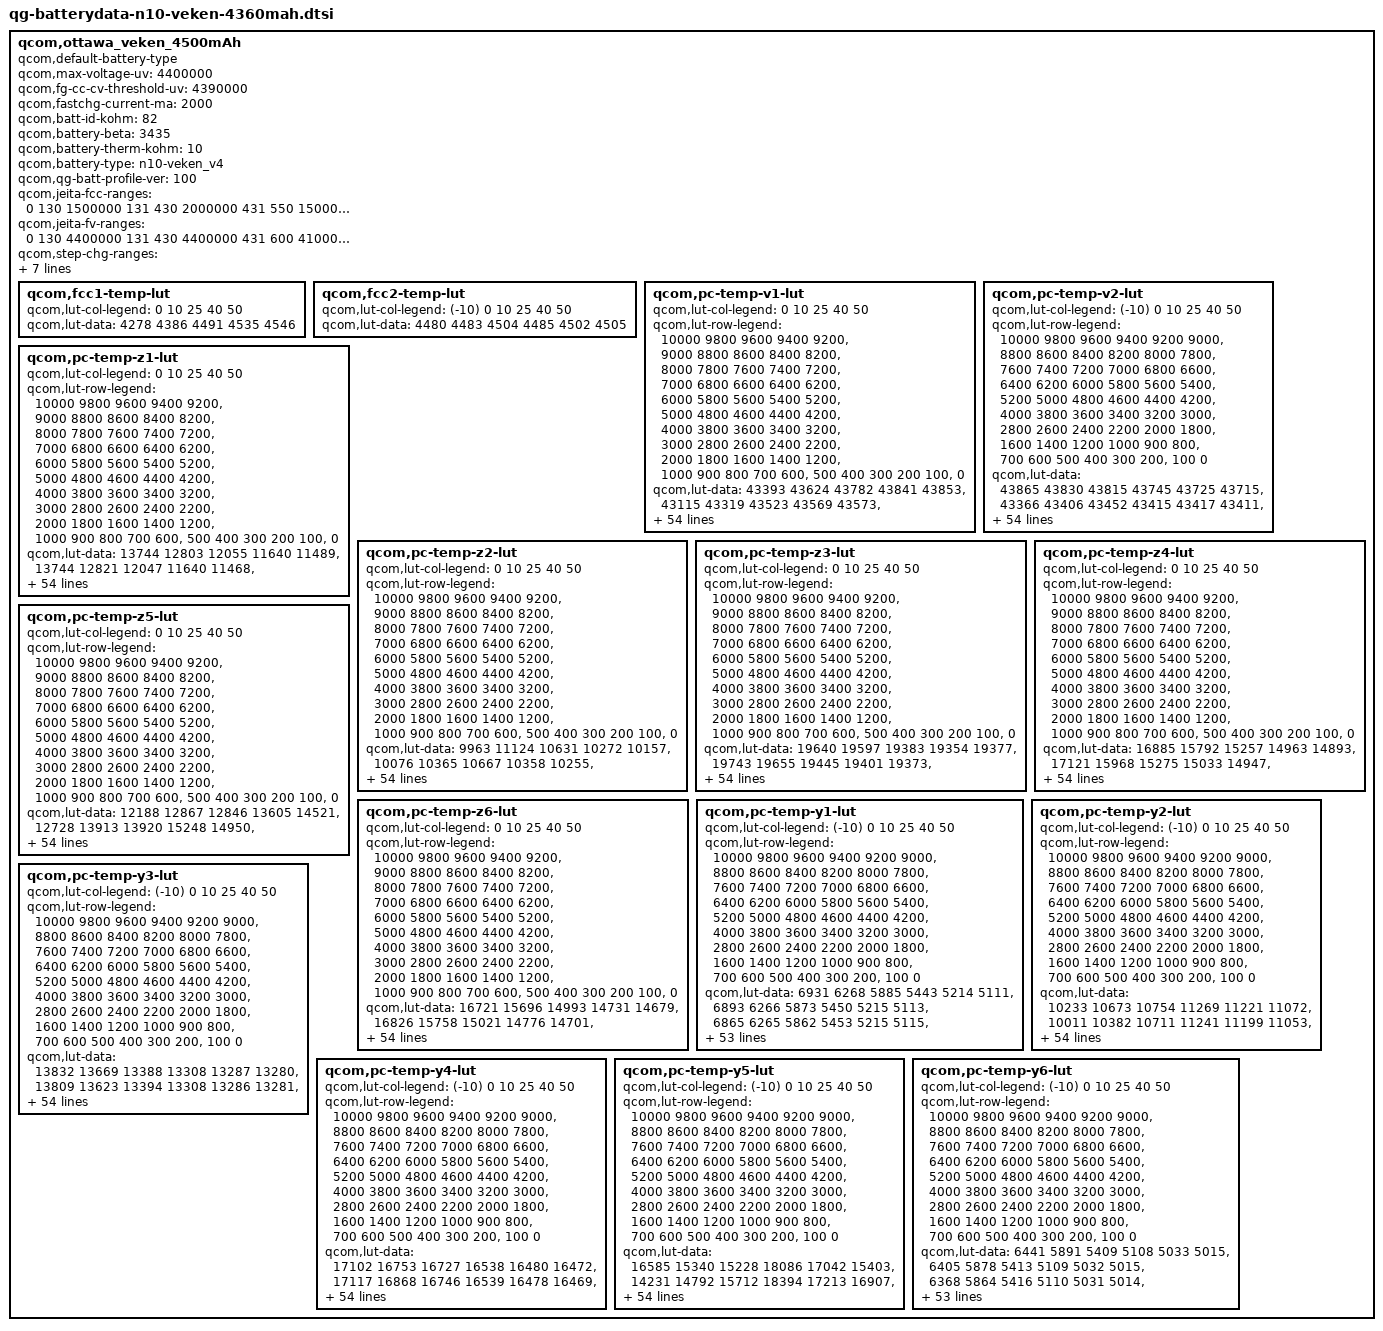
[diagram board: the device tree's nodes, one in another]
/*
 * Copyright (c) 2018, The Linux Foundation. All rights reserved.
 *
 * This program is free software; you can redistribute it and/or modify
 * it under the terms of the GNU General Public License version 2 and
 * only version 2 as published by the Free Software Foundation.
 *
 * This program is distributed in the hope that it will be useful,
 * but WITHOUT ANY WARRANTY; without even the implied warranty of
 * MERCHANTABILITY or FITNESS FOR A PARTICULAR PURPOSE.  See the
 * GNU General Public License for more details.
 */

qcom,ottawa_veken_4500mAh {
	/* 4251176_TCL_T1Pro_Veken_4500mAH_PM6150_averaged_MasterSlave_Nov29th2019 */
	qcom,default-battery-type;
	qcom,max-voltage-uv = <4400000>;
	qcom,fg-cc-cv-threshold-uv = <4390000>;
	qcom,fastchg-current-ma = <2000>;
	qcom,batt-id-kohm = <82>;
	qcom,battery-beta = <3435>;
	qcom,battery-therm-kohm = <10>;
	qcom,battery-type = "n10-veken_v4";
	qcom,qg-batt-profile-ver = <100>;

	qcom,jeita-fcc-ranges = <0  130   1500000
				131  430  2000000
				431 550   1500000
				551 600   0>;
	qcom,jeita-fv-ranges = <0   130   4400000
				131  430  4400000
				431  600  4100000>;
	qcom,step-chg-ranges = <2800000  4250000  2000000
				4250001  4400000  1800000>;
	qcom,ocv-based-step-chg;

	/* COOL = 10 DegC, WARM = 45 DegC */
	qcom,jeita-soft-thresholds = <0x2aee 0xfb3>;
	/* COLD = 0 DegC, HOT = 55 DegC */
	qcom,jeita-hard-thresholds = <0x3733 0xbc2>;
	/* COOL hys = 13 DegC, WARM hys = 42 DegC */
	qcom,jeita-soft-hys-thresholds = <0x279a 0x1124>;

	qcom,jeita-soft-fcc-ua = <2000000 2000000>;
	qcom,jeita-soft-fv-uv = <4100000 4100000>;

	qcom,fcc1-temp-lut {
		qcom,lut-col-legend = <0 10 25 40 50>;
		qcom,lut-data = <4278 4386 4491 4535 4546>;
	};

	qcom,fcc2-temp-lut {
		qcom,lut-col-legend = <(-10) 0 10 25 40 50>;
		qcom,lut-data = <4480 4483 4504 4485 4502 4505>;
	};

	qcom,pc-temp-v1-lut {
		qcom,lut-col-legend = <0 10 25 40 50>;
		qcom,lut-row-legend = <10000 9800 9600 9400 9200>,
			<9000 8800 8600 8400 8200>,
			<8000 7800 7600 7400 7200>,
			<7000 6800 6600 6400 6200>,
			<6000 5800 5600 5400 5200>,
			<5000 4800 4600 4400 4200>,
			<4000 3800 3600 3400 3200>,
			<3000 2800 2600 2400 2200>,
			<2000 1800 1600 1400 1200>,
			<1000 900 800 700 600>,
			<500 400 300 200 100>,
			<0>;
		qcom,lut-data = <43393 43624 43782 43841 43853>,
			<43115 43319 43523 43569 43573>,
			<42856 43056 43264 43311 43316>,
			<42614 42817 43011 43062 43070>,
			<42386 42585 42761 42820 42829>,
			<42167 42356 42515 42583 42593>,
			<41955 42131 42280 42349 42360>,
			<41749 41914 42052 42119 42128>,
			<41553 41702 41827 41891 41899>,
			<41373 41500 41603 41666 41673>,
			<41195 41318 41389 41443 41450>,
			<40987 41139 41199 41223 41231>,
			<40741 40927 41016 41004 41014>,
			<40489 40666 40798 40795 40805>,
			<40246 40409 40538 40592 40605>,
			<40011 40184 40302 40398 40412>,
			<39831 39979 40118 40213 40226>,
			<39708 39823 39958 40037 40048>,
			<39605 39713 39812 39869 39877>,
			<39498 39610 39681 39719 39723>,
			<39390 39489 39540 39563 39566>,
			<39285 39359 39367 39370 39377>,
			<39179 39217 39173 39148 39156>,
			<39074 39045 38970 38950 38958>,
			<38973 38866 38749 38777 38788>,
			<38877 38706 38591 38633 38644>,
			<38784 38553 38508 38529 38536>,
			<38693 38444 38446 38446 38449>,
			<38604 38377 38385 38367 38367>,
			<38525 38327 38325 38290 38284>,
			<38458 38291 38270 38220 38208>,
			<38397 38266 38218 38156 38139>,
			<38345 38244 38170 38099 38076>,
			<38301 38221 38129 38047 38018>,
			<38262 38199 38094 38003 37968>,
			<38228 38173 38059 37960 37919>,
			<38196 38146 38027 37916 37868>,
			<38159 38110 37991 37873 37815>,
			<38109 38058 37939 37813 37748>,
			<38046 37982 37856 37731 37659>,
			<37960 37889 37758 37633 37558>,
			<37836 37768 37649 37528 37450>,
			<37707 37627 37519 37404 37327>,
			<37572 37459 37353 37243 37169>,
			<37410 37302 37200 37094 37028>,
			<37287 37195 37094 37002 36941>,
			<37245 37163 37068 36971 36911>,
			<37209 37140 37045 36950 36893>,
			<37177 37123 37031 36935 36873>,
			<37136 37092 36999 36900 36833>,
			<37004 36954 36834 36711 36613>,
			<36611 36535 36417 36291 36190>,
			<36050 35982 35856 35726 35629>,
			<35301 35225 35096 34958 34860>,
			<34109 34044 33919 33769 33670>,
			<30000 30000 30000 30000 30000>;
	};

	qcom,pc-temp-v2-lut {
		qcom,lut-col-legend = <(-10) 0 10 25 40 50>;
		qcom,lut-row-legend = <10000 9800 9600 9400 9200 9000>,
			<8800 8600 8400 8200 8000 7800>,
			<7600 7400 7200 7000 6800 6600>,
			<6400 6200 6000 5800 5600 5400>,
			<5200 5000 4800 4600 4400 4200>,
			<4000 3800 3600 3400 3200 3000>,
			<2800 2600 2400 2200 2000 1800>,
			<1600 1400 1200 1000 900 800>,
			<700 600 500 400 300 200>,
			<100 0>;
		qcom,lut-data = <43865 43830 43815 43745 43725 43715>,
			<43366 43406 43452 43415 43417 43411>,
			<42943 43029 43124 43112 43130 43127>,
			<42618 42705 42837 42840 42867 42866>,
			<42366 42422 42588 42599 42626 42627>,
			<42130 42178 42350 42366 42392 42393>,
			<41874 41982 42111 42132 42157 42160>,
			<41630 41806 41877 41902 41926 41928>,
			<41447 41586 41646 41676 41699 41700>,
			<41308 41299 41412 41453 41474 41475>,
			<41178 41101 41201 41237 41254 41254>,
			<41052 41043 41039 41040 41040 41037>,
			<40911 41005 40886 40849 40831 40825>,
			<40649 40846 40677 40631 40624 40620>,
			<40090 40280 40391 40375 40416 40420>,
			<39611 39788 40125 40143 40219 40229>,
			<39405 39621 39924 39970 40042 40047>,
			<39257 39507 39745 39822 39876 39873>,
			<39089 39358 39561 39678 39714 39708>,
			<38903 39169 39380 39545 39563 39557>,
			<38730 38979 39195 39393 39396 39391>,
			<38579 38798 38995 39176 39180 39182>,
			<38447 38626 38796 38926 38950 38959>,
			<38349 38468 38626 38730 38761 38772>,
			<38275 38314 38476 38572 38600 38605>,
			<38211 38198 38340 38439 38463 38465>,
			<38151 38133 38202 38329 38352 38352>,
			<38094 38086 38080 38233 38256 38255>,
			<38039 38042 38011 38144 38169 38167>,
			<37988 38000 37969 38061 38090 38087>,
			<37937 37960 37932 37987 38020 38016>,
			<37884 37921 37895 37918 37956 37952>,
			<37830 37883 37860 37858 37897 37893>,
			<37772 37843 37826 37808 37834 37828>,
			<37713 37799 37795 37770 37770 37760>,
			<37652 37752 37759 37731 37701 37683>,
			<37590 37700 37715 37684 37624 37586>,
			<37529 37643 37663 37631 37542 37483>,
			<37465 37579 37600 37568 37464 37396>,
			<37401 37507 37525 37495 37390 37321>,
			<37337 37425 37440 37411 37309 37243>,
			<37277 37320 37342 37312 37218 37157>,
			<37216 37202 37227 37194 37113 37057>,
			<37149 37098 37086 37056 36981 36919>,
			<37070 37011 36954 36924 36859 36807>,
			<36967 36941 36866 36853 36802 36754>,
			<36910 36903 36839 36838 36793 36745>,
			<36839 36867 36816 36823 36778 36733>,
			<36749 36817 36781 36799 36756 36709>,
			<36615 36726 36712 36749 36697 36641>,
			<36387 36528 36527 36566 36455 36372>,
			<36028 36131 36110 36123 35975 35888>,
			<35480 35537 35492 35520 35347 35250>,
			<34654 34677 34618 34705 34497 34385>,
			<33273 33360 33302 33477 33279 33164>,
			<29440 28853 28714 28637 28563 28582>;
	};

	qcom,pc-temp-z1-lut {
		qcom,lut-col-legend = <0 10 25 40 50>;
		qcom,lut-row-legend = <10000 9800 9600 9400 9200>,
			<9000 8800 8600 8400 8200>,
			<8000 7800 7600 7400 7200>,
			<7000 6800 6600 6400 6200>,
			<6000 5800 5600 5400 5200>,
			<5000 4800 4600 4400 4200>,
			<4000 3800 3600 3400 3200>,
			<3000 2800 2600 2400 2200>,
			<2000 1800 1600 1400 1200>,
			<1000 900 800 700 600>,
			<500 400 300 200 100>,
			<0>;
		qcom,lut-data = <13744 12803 12055 11640 11489>,
			<13744 12821 12047 11640 11468>,
			<13761 12814 12043 11637 11471>,
			<13769 12790 12038 11633 11472>,
			<13743 12773 12030 11626 11468>,
			<13704 12768 12021 11618 11462>,
			<13692 12765 12012 11611 11458>,
			<13699 12760 12003 11603 11455>,
			<13708 12749 11998 11599 11453>,
			<13711 12737 11995 11597 11452>,
			<13698 12730 11994 11596 11451>,
			<13661 12723 11996 11597 11451>,
			<13593 12707 12000 11600 11451>,
			<13544 12665 11996 11601 11451>,
			<13526 12633 11975 11596 11451>,
			<13509 12629 11962 11590 11451>,
			<13492 12628 11964 11590 11451>,
			<13466 12630 11967 11592 11452>,
			<13443 12642 11971 11594 11453>,
			<13433 12658 11982 11597 11454>,
			<13427 12674 11991 11599 11455>,
			<13422 12692 11996 11601 11455>,
			<13415 12703 12000 11602 11456>,
			<13410 12708 12003 11603 11457>,
			<13409 12713 12005 11604 11458>,
			<13413 12720 12007 11606 11461>,
			<13420 12737 12011 11609 11463>,
			<13433 12745 12018 11614 11467>,
			<13453 12739 12022 11618 11470>,
			<13463 12729 12026 11623 11474>,
			<13462 12729 12030 11627 11478>,
			<13459 12740 12033 11632 11482>,
			<13466 12752 12036 11636 11485>,
			<13497 12759 12044 11641 11488>,
			<13523 12766 12061 11645 11493>,
			<13522 12775 12071 11650 11497>,
			<13515 12785 12071 11653 11500>,
			<13519 12798 12070 11657 11503>,
			<13538 12818 12071 11661 11505>,
			<13565 12846 12080 11668 11509>,
			<13597 12859 12090 11675 11512>,
			<13638 12857 12099 11680 11516>,
			<13641 12860 12108 11684 11520>,
			<13602 12883 12120 11687 11523>,
			<13660 12912 12123 11694 11527>,
			<13638 12883 12138 11698 11529>,
			<13667 12891 12129 11698 11529>,
			<13644 12899 12125 11699 11531>,
			<13611 12903 12136 11702 11532>,
			<13615 12895 12140 11710 11538>,
			<13631 12919 12162 11720 11545>,
			<13658 12930 12160 11731 11555>,
			<13663 12939 12176 11741 11567>,
			<13671 12970 12219 11763 11583>,
			<13671 12970 12219 11763 11583>,
			<13671 12970 12219 11763 11583>;
	};

	qcom,pc-temp-z2-lut {
		qcom,lut-col-legend = <0 10 25 40 50>;
		qcom,lut-row-legend = <10000 9800 9600 9400 9200>,
			<9000 8800 8600 8400 8200>,
			<8000 7800 7600 7400 7200>,
			<7000 6800 6600 6400 6200>,
			<6000 5800 5600 5400 5200>,
			<5000 4800 4600 4400 4200>,
			<4000 3800 3600 3400 3200>,
			<3000 2800 2600 2400 2200>,
			<2000 1800 1600 1400 1200>,
			<1000 900 800 700 600>,
			<500 400 300 200 100>,
			<0>;
		qcom,lut-data = <9963 11124 10631 10272 10157>,
			<10076 10365 10667 10358 10255>,
			<10162 10264 11033 10412 10354>,
			<10193 10242 11098 10443 10408>,
			<10200 10229 10708 10419 10392>,
			<10206 10214 10376 10389 10357>,
			<10209 10201 10438 10484 10330>,
			<10206 10191 10596 10747 10307>,
			<10201 10182 10615 10838 10296>,
			<10197 10175 10426 11039 10292>,
			<10193 10173 10275 11347 10288>,
			<10185 10171 10376 11221 10287>,
			<10158 10163 10582 10638 10292>,
			<10125 10147 10632 10391 10291>,
			<10099 10138 10510 10992 10250>,
			<10077 10142 10402 11670 10197>,
			<10068 10157 10394 11470 10196>,
			<10066 10176 10390 10685 10225>,
			<10064 10209 10397 10352 10254>,
			<10065 10247 10428 10363 10271>,
			<10071 10282 10467 10384 10293>,
			<10079 10318 10515 10450 10376>,
			<10086 10349 10559 10578 10561>,
			<10094 10380 10565 10620 10638>,
			<10102 10402 10548 10551 10540>,
			<10112 10402 10534 10481 10418>,
			<10125 10398 10522 10465 10389>,
			<10138 10396 10508 10455 10376>,
			<10153 10409 10511 10456 10379>,
			<10170 10432 10527 10485 10419>,
			<10190 10444 10540 10511 10456>,
			<10212 10453 10544 10503 10449>,
			<10234 10460 10548 10484 10416>,
			<10255 10468 10557 10478 10382>,
			<10276 10477 10572 10481 10336>,
			<10296 10489 10586 10486 10304>,
			<10315 10503 10594 10503 10323>,
			<10340 10520 10602 10535 10380>,
			<10375 10541 10616 10566 10438>,
			<10416 10566 10640 10608 10516>,
			<10456 10588 10659 10635 10571>,
			<10498 10603 10672 10639 10580>,
			<10397 10622 10679 10641 10584>,
			<9842 10648 10679 10638 10576>,
			<10019 10872 10733 10646 10533>,
			<10644 10958 10788 10562 10485>,
			<10246 11003 10795 10571 10468>,
			<10415 11128 10778 10567 10484>,
			<11495 11535 10858 10596 10493>,
			<12809 11438 10902 10673 10573>,
			<12857 11091 10914 10644 10472>,
			<10270 11041 10831 10523 10314>,
			<10331 11022 10759 10460 10267>,
			<10140 10655 10778 10420 10209>,
			<10140 10655 10778 10420 10209>,
			<10140 10655 10778 10420 10209>;
	};

	qcom,pc-temp-z3-lut {
		qcom,lut-col-legend = <0 10 25 40 50>;
		qcom,lut-row-legend = <10000 9800 9600 9400 9200>,
			<9000 8800 8600 8400 8200>,
			<8000 7800 7600 7400 7200>,
			<7000 6800 6600 6400 6200>,
			<6000 5800 5600 5400 5200>,
			<5000 4800 4600 4400 4200>,
			<4000 3800 3600 3400 3200>,
			<3000 2800 2600 2400 2200>,
			<2000 1800 1600 1400 1200>,
			<1000 900 800 700 600>,
			<500 400 300 200 100>,
			<0>;
		qcom,lut-data = <19640 19597 19383 19354 19377>,
			<19743 19655 19445 19401 19373>,
			<19781 19682 19476 19427 19397>,
			<19786 19702 19493 19439 19414>,
			<19748 19708 19509 19443 19424>,
			<19703 19701 19520 19447 19430>,
			<19688 19690 19527 19453 19431>,
			<19681 19682 19532 19465 19430>,
			<19678 19674 19530 19468 19427>,
			<19681 19667 19515 19468 19421>,
			<19688 19658 19502 19467 19412>,
			<19701 19649 19499 19455 19407>,
			<19729 19644 19499 19429 19404>,
			<19755 19641 19497 19418 19400>,
			<19762 19637 19490 19429 19393>,
			<19765 19628 19480 19441 19385>,
			<19764 19613 19471 19433 19380>,
			<19748 19595 19461 19408 19377>,
			<19722 19568 19455 19392 19374>,
			<19703 19547 19450 19385 19369>,
			<19686 19544 19448 19381 19365>,
			<19678 19545 19452 19386 19368>,
			<19681 19548 19459 19400 19378>,
			<19693 19561 19462 19404 19383>,
			<19703 19575 19460 19396 19375>,
			<19711 19578 19458 19386 19364>,
			<19718 19578 19454 19380 19360>,
			<19722 19578 19449 19377 19358>,
			<19724 19576 19449 19376 19358>,
			<19723 19574 19451 19387 19372>,
			<19717 19571 19454 19398 19388>,
			<19708 19566 19459 19404 19393>,
			<19699 19560 19464 19409 19395>,
			<19689 19556 19464 19409 19393>,
			<19678 19551 19461 19405 19385>,
			<19666 19547 19457 19398 19375>,
			<19651 19544 19453 19393 19369>,
			<19636 19540 19449 19387 19364>,
			<19617 19535 19445 19385 19363>,
			<19599 19531 19443 19384 19363>,
			<19593 19525 19440 19383 19364>,
			<19591 19518 19435 19380 19365>,
			<19537 19511 19430 19377 19366>,
			<19280 19505 19427 19378 19367>,
			<19263 19471 19414 19376 19364>,
			<19261 19451 19404 19360 19352>,
			<19261 19440 19398 19359 19348>,
			<19261 19409 19398 19358 19339>,
			<19259 19302 19375 19349 19337>,
			<19257 19260 19374 19342 19328>,
			<19257 19267 19373 19348 19349>,
			<19261 19340 19388 19357 19368>,
			<19261 19290 19393 19364 19361>,
			<19261 19285 19367 19360 19358>,
			<19261 19285 19367 19360 19358>,
			<19261 19285 19367 19360 19358>;
	};

	qcom,pc-temp-z4-lut {
		qcom,lut-col-legend = <0 10 25 40 50>;
		qcom,lut-row-legend = <10000 9800 9600 9400 9200>,
			<9000 8800 8600 8400 8200>,
			<8000 7800 7600 7400 7200>,
			<7000 6800 6600 6400 6200>,
			<6000 5800 5600 5400 5200>,
			<5000 4800 4600 4400 4200>,
			<4000 3800 3600 3400 3200>,
			<3000 2800 2600 2400 2200>,
			<2000 1800 1600 1400 1200>,
			<1000 900 800 700 600>,
			<500 400 300 200 100>,
			<0>;
		qcom,lut-data = <16885 15792 15257 14963 14893>,
			<17121 15968 15275 15033 14947>,
			<16859 15843 15179 14975 14911>,
			<16580 15569 15088 14917 14871>,
			<16327 15356 15005 14876 14837>,
			<16104 15231 14935 14837 14806>,
			<15926 15132 14869 14794 14781>,
			<15774 15054 14809 14749 14759>,
			<15644 14991 14783 14722 14743>,
			<15532 14938 14772 14693 14733>,
			<15432 14891 14764 14667 14725>,
			<15342 14851 14741 14672 14718>,
			<15257 14821 14710 14698 14711>,
			<15189 14797 14703 14709 14706>,
			<15143 14782 14717 14678 14702>,
			<15108 14777 14727 14644 14700>,
			<15072 14774 14721 14649 14695>,
			<15030 14770 14711 14672 14688>,
			<14991 14759 14701 14682 14682>,
			<14964 14746 14689 14679 14676>,
			<14946 14734 14683 14676 14671>,
			<14926 14723 14694 14687 14681>,
			<14898 14719 14719 14724 14719>,
			<14861 14734 14756 14760 14756>,
			<14831 14759 14822 14800 14793>,
			<14807 14787 14855 14826 14818>,
			<14788 14828 14845 14823 14816>,
			<14780 14848 14825 14811 14803>,
			<14775 14843 14807 14794 14786>,
			<14773 14831 14788 14769 14757>,
			<14772 14818 14770 14744 14727>,
			<14771 14800 14755 14726 14709>,
			<14769 14782 14742 14710 14694>,
			<14764 14767 14735 14704 14691>,
			<14758 14753 14730 14702 14691>,
			<14753 14741 14727 14701 14692>,
			<14748 14730 14724 14701 14693>,
			<14745 14722 14721 14703 14695>,
			<14742 14718 14721 14706 14698>,
			<14740 14714 14723 14713 14707>,
			<14736 14713 14725 14717 14714>,
			<14725 14711 14716 14711 14707>,
			<14773 14710 14705 14701 14697>,
			<15026 14703 14700 14699 14698>,
			<14954 14685 14684 14686 14689>,
			<14937 14677 14667 14674 14674>,
			<14930 14677 14661 14666 14670>,
			<14924 14701 14651 14653 14662>,
			<14918 14812 14660 14643 14641>,
			<14913 14851 14655 14640 14636>,
			<14913 14845 14664 14655 14649>,
			<14934 14788 14665 14666 14653>,
			<14956 14856 14663 14663 14662>,
			<14972 14873 14696 14671 14669>,
			<14972 14873 14696 14671 14669>,
			<14972 14873 14696 14671 14669>;
	};

	qcom,pc-temp-z5-lut {
		qcom,lut-col-legend = <0 10 25 40 50>;
		qcom,lut-row-legend = <10000 9800 9600 9400 9200>,
			<9000 8800 8600 8400 8200>,
			<8000 7800 7600 7400 7200>,
			<7000 6800 6600 6400 6200>,
			<6000 5800 5600 5400 5200>,
			<5000 4800 4600 4400 4200>,
			<4000 3800 3600 3400 3200>,
			<3000 2800 2600 2400 2200>,
			<2000 1800 1600 1400 1200>,
			<1000 900 800 700 600>,
			<500 400 300 200 100>,
			<0>;
		qcom,lut-data = <12188 12867 12846 13605 14521>,
			<12728 13913 13920 15248 14950>,
			<13269 14609 14682 16708 16769>,
			<13643 15119 15472 17770 18403>,
			<13844 15554 16628 18504 19620>,
			<14018 15926 17971 19165 20631>,
			<14216 16289 19500 20735 21454>,
			<14448 16756 21032 23823 22260>,
			<14671 17326 21646 25486 22772>,
			<14847 17987 21691 28590 22877>,
			<15029 18774 21847 32652 22937>,
			<15355 19764 23733 31722 23232>,
			<16018 21118 27035 26434 24127>,
			<16645 23294 28384 24319 24647>,
			<17006 24872 28918 32325 24114>,
			<17329 24957 28925 41212 23401>,
			<17475 24411 27627 38690 23573>,
			<17228 23700 25743 29078 24700>,
			<16843 22451 25892 25145 25730>,
			<16713 21493 28947 25539 26268>,
			<16684 22252 33007 26312 26883>,
			<16677 25437 39283 30188 29297>,
			<17286 30109 45835 38578 34491>,
			<19164 41217 46475 41118 36407>,
			<21415 52548 42035 33266 29970>,
			<24280 54738 37409 24407 21966>,
			<27650 53178 32621 21235 19178>,
			<31527 51217 27950 19264 17548>,
			<36083 48995 27160 18872 17201>,
			<38880 46212 27394 20197 19081>,
			<39999 43945 27952 22345 21926>,
			<40687 41643 30562 25328 25018>,
			<40762 40045 34754 29345 28676>,
			<40056 39423 38012 32056 29850>,
			<38871 39222 41069 34107 29859>,
			<36720 39556 42479 35178 29754>,
			<33287 40604 42412 34738 29518>,
			<30798 41511 42229 33620 29103>,
			<28649 41745 41780 32637 28701>,
			<26806 41827 40275 31767 28155>,
			<27048 41563 38394 30706 27667>,
			<29742 38580 35903 28670 27140>,
			<27377 36527 33978 26985 26703>,
			<12208 37238 33276 27710 27540>,
			<11897 36443 33534 28761 27769>,
			<11918 32799 33483 24510 23701>,
			<11875 27905 30201 24492 22265>,
			<11855 20759 31274 26299 20689>,
			<11843 12718 21861 24882 24239>,
			<11827 11804 22251 23732 23230>,
			<11869 12201 22033 22105 27815>,
			<11916 16556 23149 19874 26577>,
			<11769 12200 22674 20403 20943>,
			<11606 11883 16988 18240 18167>,
			<11606 11883 16988 18240 18167>,
			<11606 11883 16988 18240 18167>;
	};

	qcom,pc-temp-z6-lut {
		qcom,lut-col-legend = <0 10 25 40 50>;
		qcom,lut-row-legend = <10000 9800 9600 9400 9200>,
			<9000 8800 8600 8400 8200>,
			<8000 7800 7600 7400 7200>,
			<7000 6800 6600 6400 6200>,
			<6000 5800 5600 5400 5200>,
			<5000 4800 4600 4400 4200>,
			<4000 3800 3600 3400 3200>,
			<3000 2800 2600 2400 2200>,
			<2000 1800 1600 1400 1200>,
			<1000 900 800 700 600>,
			<500 400 300 200 100>,
			<0>;
		qcom,lut-data = <16721 15696 14993 14731 14679>,
			<16826 15758 15021 14776 14701>,
			<16688 15710 14994 14766 14697>,
			<16529 15576 14964 14754 14692>,
			<16364 15461 14928 14737 14683>,
			<16213 15385 14897 14720 14671>,
			<16101 15323 14870 14705 14661>,
			<16012 15272 14845 14692 14651>,
			<15936 15231 14826 14680 14642>,
			<15873 15195 14812 14668 14634>,
			<15817 15162 14799 14658 14625>,
			<15763 15133 14787 14652 14619>,
			<15712 15104 14775 14649 14614>,
			<15668 15074 14768 14645 14609>,
			<15633 15051 14763 14638 14604>,
			<15603 15040 14759 14631 14598>,
			<15572 15032 14752 14626 14593>,
			<15538 15022 14744 14621 14589>,
			<15504 15007 14738 14617 14584>,
			<15480 14995 14732 14613 14579>,
			<15462 14994 14730 14610 14575>,
			<15447 14993 14737 14617 14580>,
			<15432 14994 14753 14641 14603>,
			<15419 15008 14773 14658 14621>,
			<15413 15029 14801 14671 14632>,
			<15412 15046 14815 14678 14638>,
			<15411 15065 14810 14675 14637>,
			<15413 15073 14800 14669 14630>,
			<15416 15072 14793 14663 14624>,
			<15417 15068 14788 14658 14620>,
			<15417 15063 14784 14654 14616>,
			<15416 15054 14781 14650 14612>,
			<15414 15045 14778 14647 14608>,
			<15410 15038 14776 14644 14604>,
			<15406 15033 14775 14641 14600>,
			<15403 15030 14773 14638 14596>,
			<15401 15029 14771 14636 14594>,
			<15400 15028 14769 14635 14592>,
			<15400 15029 14769 14635 14592>,
			<15400 15031 14772 14638 14596>,
			<15401 15034 14774 14640 14600>,
			<15408 15035 14770 14636 14598>,
			<15409 15037 14766 14632 14595>,
			<15402 15039 14766 14632 14596>,
			<15377 15027 14758 14627 14591>,
			<15372 15017 14749 14615 14579>,
			<15369 15013 14744 14611 14575>,
			<15368 15009 14740 14605 14567>,
			<15368 15005 14734 14596 14557>,
			<15370 15006 14734 14593 14551>,
			<15380 15015 14743 14604 14568>,
			<15399 15035 14756 14617 14583>,
			<15419 15050 14764 14622 14587>,
			<15443 15070 14773 14628 14592>,
			<15443 15070 14773 14628 14592>,
			<15443 15070 14773 14628 14592>;
	};

	qcom,pc-temp-y1-lut {
		qcom,lut-col-legend = <(-10) 0 10 25 40 50>;
		qcom,lut-row-legend = <10000 9800 9600 9400 9200 9000>,
			<8800 8600 8400 8200 8000 7800>,
			<7600 7400 7200 7000 6800 6600>,
			<6400 6200 6000 5800 5600 5400>,
			<5200 5000 4800 4600 4400 4200>,
			<4000 3800 3600 3400 3200 3000>,
			<2800 2600 2400 2200 2000 1800>,
			<1600 1400 1200 1000 900 800>,
			<700 600 500 400 300 200>,
			<100 0>;
		qcom,lut-data = <6931 6268 5885 5443 5214 5111>,
			<6893 6266 5873 5450 5215 5113>,
			<6865 6265 5862 5453 5215 5115>,
			<6847 6264 5852 5453 5215 5115>,
			<6837 6264 5846 5452 5214 5116>,
			<6834 6264 5843 5451 5212 5115>,
			<6843 6267 5849 5449 5210 5114>,
			<6857 6274 5858 5445 5207 5113>,
			<6860 6283 5858 5445 5205 5111>,
			<6858 6302 5848 5447 5204 5110>,
			<6856 6314 5841 5448 5203 5108>,
			<6860 6300 5845 5445 5202 5108>,
			<6866 6278 5852 5441 5202 5107>,
			<6863 6274 5855 5440 5201 5107>,
			<6850 6280 5863 5442 5198 5108>,
			<6842 6286 5869 5445 5196 5109>,
			<6853 6288 5867 5451 5199 5108>,
			<6872 6287 5863 5460 5203 5107>,
			<6878 6289 5861 5461 5204 5107>,
			<6888 6307 5860 5453 5203 5109>,
			<6897 6322 5859 5448 5203 5110>,
			<6889 6313 5859 5450 5203 5111>,
			<6867 6295 5858 5453 5205 5112>,
			<6857 6291 5860 5456 5207 5113>,
			<6848 6297 5866 5459 5211 5115>,
			<6842 6302 5869 5462 5214 5117>,
			<6855 6300 5868 5467 5216 5119>,
			<6880 6298 5867 5472 5218 5120>,
			<6896 6302 5866 5478 5221 5123>,
			<6908 6316 5864 5486 5224 5125>,
			<6915 6324 5863 5492 5228 5128>,
			<6898 6310 5866 5492 5232 5131>,
			<6859 6286 5870 5491 5236 5135>,
			<6840 6283 5872 5491 5239 5138>,
			<6830 6304 5873 5495 5242 5139>,
			<6824 6320 5873 5499 5245 5141>,
			<6831 6313 5876 5502 5247 5143>,
			<6844 6302 5883 5505 5250 5146>,
			<6847 6299 5885 5506 5252 5148>,
			<6848 6296 5884 5510 5256 5149>,
			<6851 6292 5884 5514 5259 5151>,
			<6861 6284 5885 5518 5263 5154>,
			<6873 6278 5888 5524 5267 5158>,
			<6857 6301 5892 5533 5273 5161>,
			<6841 6315 5890 5550 5287 5167>,
			<6893 6327 5904 5569 5290 5172>,
			<6916 6348 5919 5560 5291 5173>,
			<6967 6338 5911 5556 5290 5171>,
			<6953 6346 5926 5558 5290 5170>,
			<6942 6384 5912 5558 5290 5169>,
			<6931 6395 5916 5560 5289 5171>,
			<6989 6394 5921 5567 5297 5175>,
			<6964 6381 5944 5576 5310 5185>,
			<7050 6424 5972 5589 5327 5197>,
			<7050 6424 5972 5589 5327 5197>,
			<7050 6424 5972 5589 5327 5197>;
	};

	qcom,pc-temp-y2-lut {
		qcom,lut-col-legend = <(-10) 0 10 25 40 50>;
		qcom,lut-row-legend = <10000 9800 9600 9400 9200 9000>,
			<8800 8600 8400 8200 8000 7800>,
			<7600 7400 7200 7000 6800 6600>,
			<6400 6200 6000 5800 5600 5400>,
			<5200 5000 4800 4600 4400 4200>,
			<4000 3800 3600 3400 3200 3000>,
			<2800 2600 2400 2200 2000 1800>,
			<1600 1400 1200 1000 900 800>,
			<700 600 500 400 300 200>,
			<100 0>;
		qcom,lut-data = <10233 10673 10754 11269 11221 11072>,
			<10011 10382 10711 11241 11199 11053>,
			<9914 10199 10686 11212 11158 11022>,
			<9912 10099 10674 11184 11110 10988>,
			<9973 10057 10670 11157 11068 10957>,
			<10068 10049 10672 11132 11043 10940>,
			<10284 10110 10694 11109 11029 10932>,
			<10545 10235 10727 11087 11016 10926>,
			<10517 10344 10714 11060 11001 10912>,
			<10038 10475 10618 11027 10973 10878>,
			<9702 10544 10558 10996 10955 10854>,
			<9822 10503 10689 10963 10958 10852>,
			<10040 10439 10892 10936 10965 10855>,
			<10066 10450 10934 10939 10973 10860>,
			<9850 10607 10936 10997 10982 10867>,
			<9680 10791 10939 11064 10995 10877>,
			<9675 10960 10990 11111 11021 10900>,
			<9674 11110 11077 11156 11063 10937>,
			<9673 11137 11137 11217 11119 10988>,
			<9673 11103 11186 11312 11208 11064>,
			<9672 11044 11222 11366 11265 11129>,
			<9671 10887 11248 11358 11271 11175>,
			<9670 10614 11266 11343 11267 11209>,
			<9669 10362 11269 11343 11266 11212>,
			<9668 9968 11266 11369 11276 11192>,
			<9668 9724 11259 11396 11292 11182>,
			<9667 9707 11155 11410 11317 11192>,
			<9666 9699 11029 11423 11350 11210>,
			<9666 9692 11014 11440 11389 11236>,
			<9665 9686 10945 11469 11442 11290>,
			<9664 9681 10870 11489 11473 11336>,
			<9664 9677 10693 11487 11482 11361>,
			<9663 9673 10508 11481 11488 11379>,
			<9663 9670 10576 11475 11484 11384>,
			<9662 9668 10842 11460 11461 11386>,
			<9662 9666 10937 11441 11433 11380>,
			<9661 9664 10471 11418 11404 11331>,
			<9661 9663 9842 11380 11374 11260>,
			<9661 9662 9711 11340 11357 11224>,
			<9661 9662 9690 11295 11342 11202>,
			<9661 9661 9679 11241 11336 11189>,
			<9661 9661 9673 11176 11339 11213>,
			<9660 9660 9669 11100 11335 11239>,
			<9660 9660 9666 10997 11299 11191>,
			<9659 9659 9663 10894 11193 11057>,
			<9659 9659 9663 10866 11131 10986>,
			<9659 9659 9662 10862 11122 10982>,
			<9658 9658 9661 10848 11125 10998>,
			<9658 9658 9660 10833 11120 11027>,
			<9658 9658 9659 10835 11185 11062>,
			<9658 9657 9659 10790 11142 11008>,
			<9657 9657 9658 10696 11041 10901>,
			<9656 9656 9657 10596 10953 10839>,
			<9654 9656 9656 10530 10895 10701>,
			<9654 9656 9656 10530 10895 10701>,
			<9654 9656 9656 10530 10895 10701>;
	};

	qcom,pc-temp-y3-lut {
		qcom,lut-col-legend = <(-10) 0 10 25 40 50>;
		qcom,lut-row-legend = <10000 9800 9600 9400 9200 9000>,
			<8800 8600 8400 8200 8000 7800>,
			<7600 7400 7200 7000 6800 6600>,
			<6400 6200 6000 5800 5600 5400>,
			<5200 5000 4800 4600 4400 4200>,
			<4000 3800 3600 3400 3200 3000>,
			<2800 2600 2400 2200 2000 1800>,
			<1600 1400 1200 1000 900 800>,
			<700 600 500 400 300 200>,
			<100 0>;
		qcom,lut-data = <13832 13669 13388 13308 13287 13280>,
			<13809 13623 13394 13308 13286 13281>,
			<13779 13595 13399 13309 13286 13282>,
			<13749 13580 13402 13310 13286 13283>,
			<13726 13574 13404 13311 13286 13284>,
			<13716 13573 13405 13312 13287 13285>,
			<13720 13589 13403 13313 13287 13285>,
			<13726 13614 13400 13314 13288 13286>,
			<13706 13598 13406 13315 13288 13286>,
			<13585 13471 13436 13315 13289 13287>,
			<13497 13384 13455 13316 13290 13287>,
			<13499 13395 13415 13319 13293 13288>,
			<13508 13417 13355 13323 13296 13288>,
			<13506 13423 13349 13323 13297 13288>,
			<13490 13421 13371 13318 13298 13289>,
			<13477 13418 13384 13315 13298 13289>,
			<13472 13412 13381 13315 13299 13291>,
			<13470 13402 13373 13315 13301 13294>,
			<13471 13391 13366 13316 13301 13295>,
			<13475 13375 13360 13316 13299 13295>,
			<13476 13364 13354 13317 13297 13295>,
			<13467 13363 13347 13314 13294 13293>,
			<13453 13363 13340 13308 13291 13287>,
			<13451 13356 13334 13304 13289 13284>,
			<13465 13318 13329 13302 13287 13282>,
			<13482 13289 13321 13300 13285 13281>,
			<13497 13295 13304 13300 13285 13280>,
			<13514 13309 13285 13300 13284 13280>,
			<13534 13322 13277 13300 13284 13280>,
			<13562 13335 13266 13299 13284 13280>,
			<13592 13351 13259 13298 13285 13280>,
			<13622 13374 13268 13297 13285 13280>,
			<13654 13405 13284 13297 13285 13280>,
			<13686 13436 13297 13297 13286 13281>,
			<13718 13467 13316 13298 13285 13281>,
			<13752 13499 13331 13299 13285 13281>,
			<13791 13534 13339 13299 13285 13280>,
			<13833 13570 13348 13300 13284 13279>,
			<13870 13607 13359 13301 13285 13279>,
			<13901 13646 13371 13303 13285 13281>,
			<13933 13683 13386 13305 13286 13283>,
			<13972 13712 13414 13307 13287 13284>,
			<14016 13740 13452 13309 13288 13285>,
			<14064 13772 13493 13309 13288 13283>,
			<14120 13816 13545 13310 13287 13283>,
			<14130 13837 13547 13314 13289 13287>,
			<14144 13848 13583 13316 13294 13291>,
			<14199 13892 13629 13321 13297 13293>,
			<14259 13940 13676 13326 13300 13295>,
			<14324 13985 13720 13334 13302 13295>,
			<14392 14027 13762 13335 13297 13290>,
			<14482 14078 13810 13333 13295 13291>,
			<14614 14172 13906 13341 13301 13294>,
			<15087 14292 14005 13352 13310 13302>,
			<15087 14292 14005 13352 13310 13302>,
			<15087 14292 14005 13352 13310 13302>;
	};

	qcom,pc-temp-y4-lut {
		qcom,lut-col-legend = <(-10) 0 10 25 40 50>;
		qcom,lut-row-legend = <10000 9800 9600 9400 9200 9000>,
			<8800 8600 8400 8200 8000 7800>,
			<7600 7400 7200 7000 6800 6600>,
			<6400 6200 6000 5800 5600 5400>,
			<5200 5000 4800 4600 4400 4200>,
			<4000 3800 3600 3400 3200 3000>,
			<2800 2600 2400 2200 2000 1800>,
			<1600 1400 1200 1000 900 800>,
			<700 600 500 400 300 200>,
			<100 0>;
		qcom,lut-data = <17102 16753 16727 16538 16480 16472>,
			<17117 16868 16746 16539 16478 16469>,
			<17126 16961 16776 16540 16477 16466>,
			<17130 17029 16808 16541 16475 16463>,
			<17131 17071 16834 16541 16475 16461>,
			<17130 17085 16844 16541 16475 16460>,
			<17048 17059 16843 16540 16475 16461>,
			<16915 17016 16840 16538 16476 16461>,
			<16958 17038 16824 16539 16477 16463>,
			<17380 17229 16761 16544 16480 16465>,
			<17676 17413 16722 16549 16482 16467>,
			<17651 17513 16873 16555 16482 16470>,
			<17582 17586 17101 16561 16483 16474>,
			<17456 17529 17113 16565 16484 16478>,
			<17130 17108 16957 16570 16490 16484>,
			<16908 16807 16848 16578 16498 16489>,
			<16894 16826 16835 16600 16508 16494>,
			<16886 16865 16826 16637 16521 16499>,
			<16865 16870 16815 16663 16542 16510>,
			<16803 16841 16801 16685 16575 16534>,
			<16754 16798 16780 16696 16593 16548>,
			<16745 16733 16734 16655 16570 16537>,
			<16739 16661 16674 16576 16528 16516>,
			<16735 16647 16633 16534 16500 16495>,
			<16731 16665 16602 16511 16476 16472>,
			<16729 16678 16583 16499 16466 16461>,
			<16729 16676 16574 16497 16467 16462>,
			<16729 16670 16569 16496 16470 16465>,
			<16728 16667 16576 16495 16474 16470>,
			<16726 16668 16610 16495 16481 16478>,
			<16724 16669 16633 16494 16490 16487>,
			<16726 16667 16620 16491 16499 16499>,
			<16731 16665 16596 16487 16508 16510>,
			<16735 16666 16586 16486 16509 16512>,
			<16740 16675 16571 16492 16506 16510>,
			<16744 16685 16569 16498 16502 16508>,
			<16749 16694 16600 16502 16489 16491>,
			<16756 16702 16640 16505 16474 16470>,
			<16765 16706 16660 16509 16472 16468>,
			<16781 16707 16673 16514 16474 16472>,
			<16800 16707 16679 16520 16478 16478>,
			<16819 16695 16678 16530 16485 16486>,
			<16839 16677 16676 16542 16489 16491>,
			<16866 16671 16667 16552 16478 16469>,
			<16882 16673 16658 16555 16474 16458>,
			<16844 16678 16645 16546 16475 16465>,
			<16821 16686 16655 16550 16488 16490>,
			<16840 16708 16674 16568 16514 16523>,
			<16850 16741 16703 16595 16550 16559>,
			<16857 16775 16748 16628 16574 16575>,
			<16857 16783 16762 16626 16528 16509>,
			<16852 16760 16732 16600 16496 16479>,
			<16858 16754 16719 16614 16508 16482>,
			<17046 16785 16734 16648 16541 16507>,
			<17046 16785 16734 16648 16541 16507>,
			<17046 16785 16734 16648 16541 16507>;
	};

	qcom,pc-temp-y5-lut {
		qcom,lut-col-legend = <(-10) 0 10 25 40 50>;
		qcom,lut-row-legend = <10000 9800 9600 9400 9200 9000>,
			<8800 8600 8400 8200 8000 7800>,
			<7600 7400 7200 7000 6800 6600>,
			<6400 6200 6000 5800 5600 5400>,
			<5200 5000 4800 4600 4400 4200>,
			<4000 3800 3600 3400 3200 3000>,
			<2800 2600 2400 2200 2000 1800>,
			<1600 1400 1200 1000 900 800>,
			<700 600 500 400 300 200>,
			<100 0>;
		qcom,lut-data = <16585 15340 15228 18086 17042 15403>,
			<14231 14792 15712 18394 17213 16907>,
			<13450 14543 16330 18589 17122 18026>,
			<13874 14539 16944 18695 16886 18789>,
			<15138 14730 17415 18740 16624 19225>,
			<16877 15066 17602 18749 16454 19362>,
			<20253 17518 17520 18683 16262 19084>,
			<24042 21150 17396 18511 15994 18540>,
			<23786 20975 17877 18221 15795 18054>,
			<17955 15612 20332 17559 15573 17465>,
			<13913 11906 21830 16855 15460 16918>,
			<17108 14418 18696 16252 15984 16501>,
			<22546 18653 14049 15720 16791 16119>,
			<22928 19469 14273 15458 16831 15687>,
			<17443 18543 19465 15314 16235 15155>,
			<13436 17824 22722 15214 15756 14892>,
			<13881 18682 22058 15126 15529 15094>,
			<14845 20435 21061 15075 15338 15400>,
			<15261 21356 21118 15388 15268 15429>,
			<15479 21744 22336 17438 15156 15256>,
			<15565 22239 23298 19792 15192 15183>,
			<14621 23891 23595 21746 17233 16842>,
			<12948 26097 23793 23449 20174 19267>,
			<12526 25489 23919 23886 20726 19781>,
			<12569 17760 24060 23666 20641 19809>,
			<12603 11878 24109 23505 20488 19731>,
			<12607 11881 20340 23800 19821 18965>,
			<12607 12112 14697 24183 18924 17816>,
			<12640 12203 12933 24282 18783 17307>,
			<12873 12278 12121 24249 18956 17027>,
			<13100 12403 11764 24211 19223 16923>,
			<13176 12760 12353 24195 19821 17065>,
			<13205 13307 13546 24358 20687 17407>,
			<13177 13595 14786 24492 21401 18143>,
			<13111 13781 16792 24470 22049 19814>,
			<13051 13910 17745 24264 22415 20725>,
			<13040 14035 16629 23537 22340 20403>,
			<13058 14214 14997 22336 22171 19912>,
			<13022 14354 14543 21352 22120 19981>,
			<12881 14679 14380 20562 21662 20605>,
			<12779 14953 14323 19774 21208 21065>,
			<12888 14713 14467 18881 20700 21383>,
			<13163 14150 14622 17956 20379 21509>,
			<13417 13801 14294 16871 20340 20439>,
			<13695 13672 14011 16474 18724 19208>,
			<13932 13816 13944 17383 18238 18386>,
			<14147 13640 14045 17507 18689 17847>,
			<14245 13928 14206 17290 17961 17057>,
			<14723 14083 14142 17034 17555 16495>,
			<15109 14404 14139 17207 17669 16303>,
			<15076 14871 14389 17538 18479 17101>,
			<14872 14468 14240 17565 18901 18981>,
			<14276 14375 14262 17885 19804 19028>,
			<13001 14369 14220 18328 23134 23661>,
			<13001 14369 14220 18328 23134 23661>,
			<13001 14369 14220 18328 23134 23661>;
	};

	qcom,pc-temp-y6-lut {
		qcom,lut-col-legend = <(-10) 0 10 25 40 50>;
		qcom,lut-row-legend = <10000 9800 9600 9400 9200 9000>,
			<8800 8600 8400 8200 8000 7800>,
			<7600 7400 7200 7000 6800 6600>,
			<6400 6200 6000 5800 5600 5400>,
			<5200 5000 4800 4600 4400 4200>,
			<4000 3800 3600 3400 3200 3000>,
			<2800 2600 2400 2200 2000 1800>,
			<1600 1400 1200 1000 900 800>,
			<700 600 500 400 300 200>,
			<100 0>;
		qcom,lut-data = <6441 5891 5409 5108 5033 5015>,
			<6405 5878 5413 5109 5032 5015>,
			<6368 5864 5416 5110 5031 5014>,
			<6332 5850 5417 5110 5031 5014>,
			<6297 5839 5418 5110 5031 5015>,
			<6262 5831 5418 5111 5031 5015>,
			<6221 5827 5414 5111 5031 5015>,
			<6184 5823 5406 5110 5032 5016>,
			<6174 5813 5401 5111 5033 5016>,
			<6173 5787 5396 5111 5034 5017>,
			<6174 5771 5393 5113 5035 5018>,
			<6176 5796 5407 5116 5037 5019>,
			<6175 5837 5427 5120 5039 5021>,
			<6150 5828 5426 5121 5041 5022>,
			<6039 5717 5399 5119 5043 5024>,
			<5961 5637 5377 5118 5045 5026>,
			<5961 5640 5371 5125 5048 5029>,
			<5961 5648 5367 5137 5054 5032>,
			<5960 5648 5361 5145 5059 5036>,
			<5952 5637 5353 5151 5067 5044>,
			<5944 5624 5343 5154 5071 5047>,
			<5940 5611 5326 5141 5063 5042>,
			<5936 5599 5306 5115 5048 5032>,
			<5937 5588 5294 5101 5038 5023>,
			<5950 5577 5286 5093 5030 5015>,
			<5966 5571 5279 5089 5026 5011>,
			<5980 5581 5271 5090 5027 5012>,
			<5995 5604 5265 5091 5027 5012>,
			<6013 5627 5266 5091 5028 5013>,
			<6035 5649 5278 5092 5031 5016>,
			<6060 5674 5294 5092 5034 5019>,
			<6086 5702 5310 5093 5038 5023>,
			<6113 5732 5330 5093 5041 5027>,
			<6140 5765 5353 5095 5041 5027>,
			<6166 5802 5381 5099 5041 5027>,
			<6193 5840 5412 5105 5040 5027>,
			<6225 5876 5447 5109 5037 5022>,
			<6260 5913 5485 5114 5033 5015>,
			<6294 5948 5526 5120 5033 5015>,
			<6325 5983 5569 5127 5034 5018>,
			<6357 6014 5616 5136 5037 5021>,
			<6393 6037 5666 5149 5040 5025>,
			<6433 6058 5716 5164 5043 5027>,
			<6477 6085 5764 5180 5041 5019>,
			<6531 6124 5819 5199 5040 5017>,
			<6550 6148 5826 5201 5044 5023>,
			<6564 6165 5861 5205 5051 5033>,
			<6616 6205 5906 5220 5061 5044>,
			<6671 6254 5956 5241 5073 5055>,
			<6728 6304 6011 5262 5080 5060>,
			<6791 6343 6053 5268 5064 5038>,
			<6869 6382 6092 5273 5055 5031>,
			<6987 6461 6172 5318 5065 5035>,
			<7491 6577 6267 5371 5084 5050>,
			<7491 6577 6267 5371 5084 5050>,
			<7491 6577 6267 5371 5084 5050>;
	};
};
